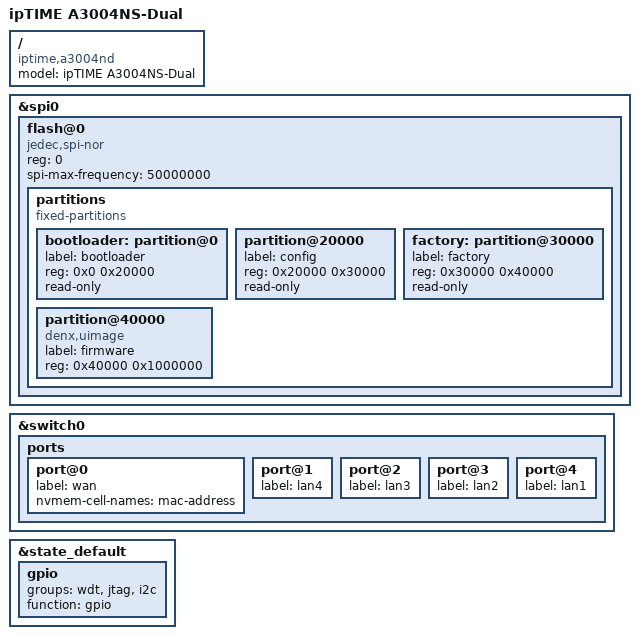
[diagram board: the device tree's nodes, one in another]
// SPDX-License-Identifier: GPL-2.0-or-later OR MIT

#include "mt7621.dtsi"

#include <dt-bindings/gpio/gpio.h>
#include <dt-bindings/input/input.h>

/ {
	compatible = "iptime,a3004nd", "mediatek,mt7621-soc";
	model = "ipTIME A3004NS-Dual";
};

&spi0 {
	status = "okay";

	flash@0 {
		compatible = "jedec,spi-nor";
		reg = <0>;
		spi-max-frequency = <50000000>;

		partitions {
			compatible = "fixed-partitions";
			#address-cells = <1>;
			#size-cells = <1>;

			bootloader: partition@0 {
				label = "bootloader";
				reg = <0x0 0x20000>;
				read-only;
			};

			partition@20000 {
				label = "config";
				reg = <0x20000 0x30000>;
				read-only;
			};

			factory: partition@30000 {
				label = "factory";
				reg = <0x30000 0x40000>;
				read-only;
			};

			partition@40000 {
				label = "firmware";
				reg = <0x40000 0x1000000>;
				compatible = "denx,uimage";
			};
		};
	};
};

&switch0 {
	ports {
		port@0 {
			status = "okay";
			label = "wan";
			nvmem-cell-names = "mac-address";
		};

		port@1 {
			status = "okay";
			label = "lan4";
		};

		port@2 {
			status = "okay";
			label = "lan3";
		};

		port@3 {
			status = "okay";
			label = "lan2";
		};

		port@4 {
			status = "okay";
			label = "lan1";
		};
	};
};

&state_default {
	gpio {
		groups = "wdt", "jtag", "i2c";
		function = "gpio";
	};
};
